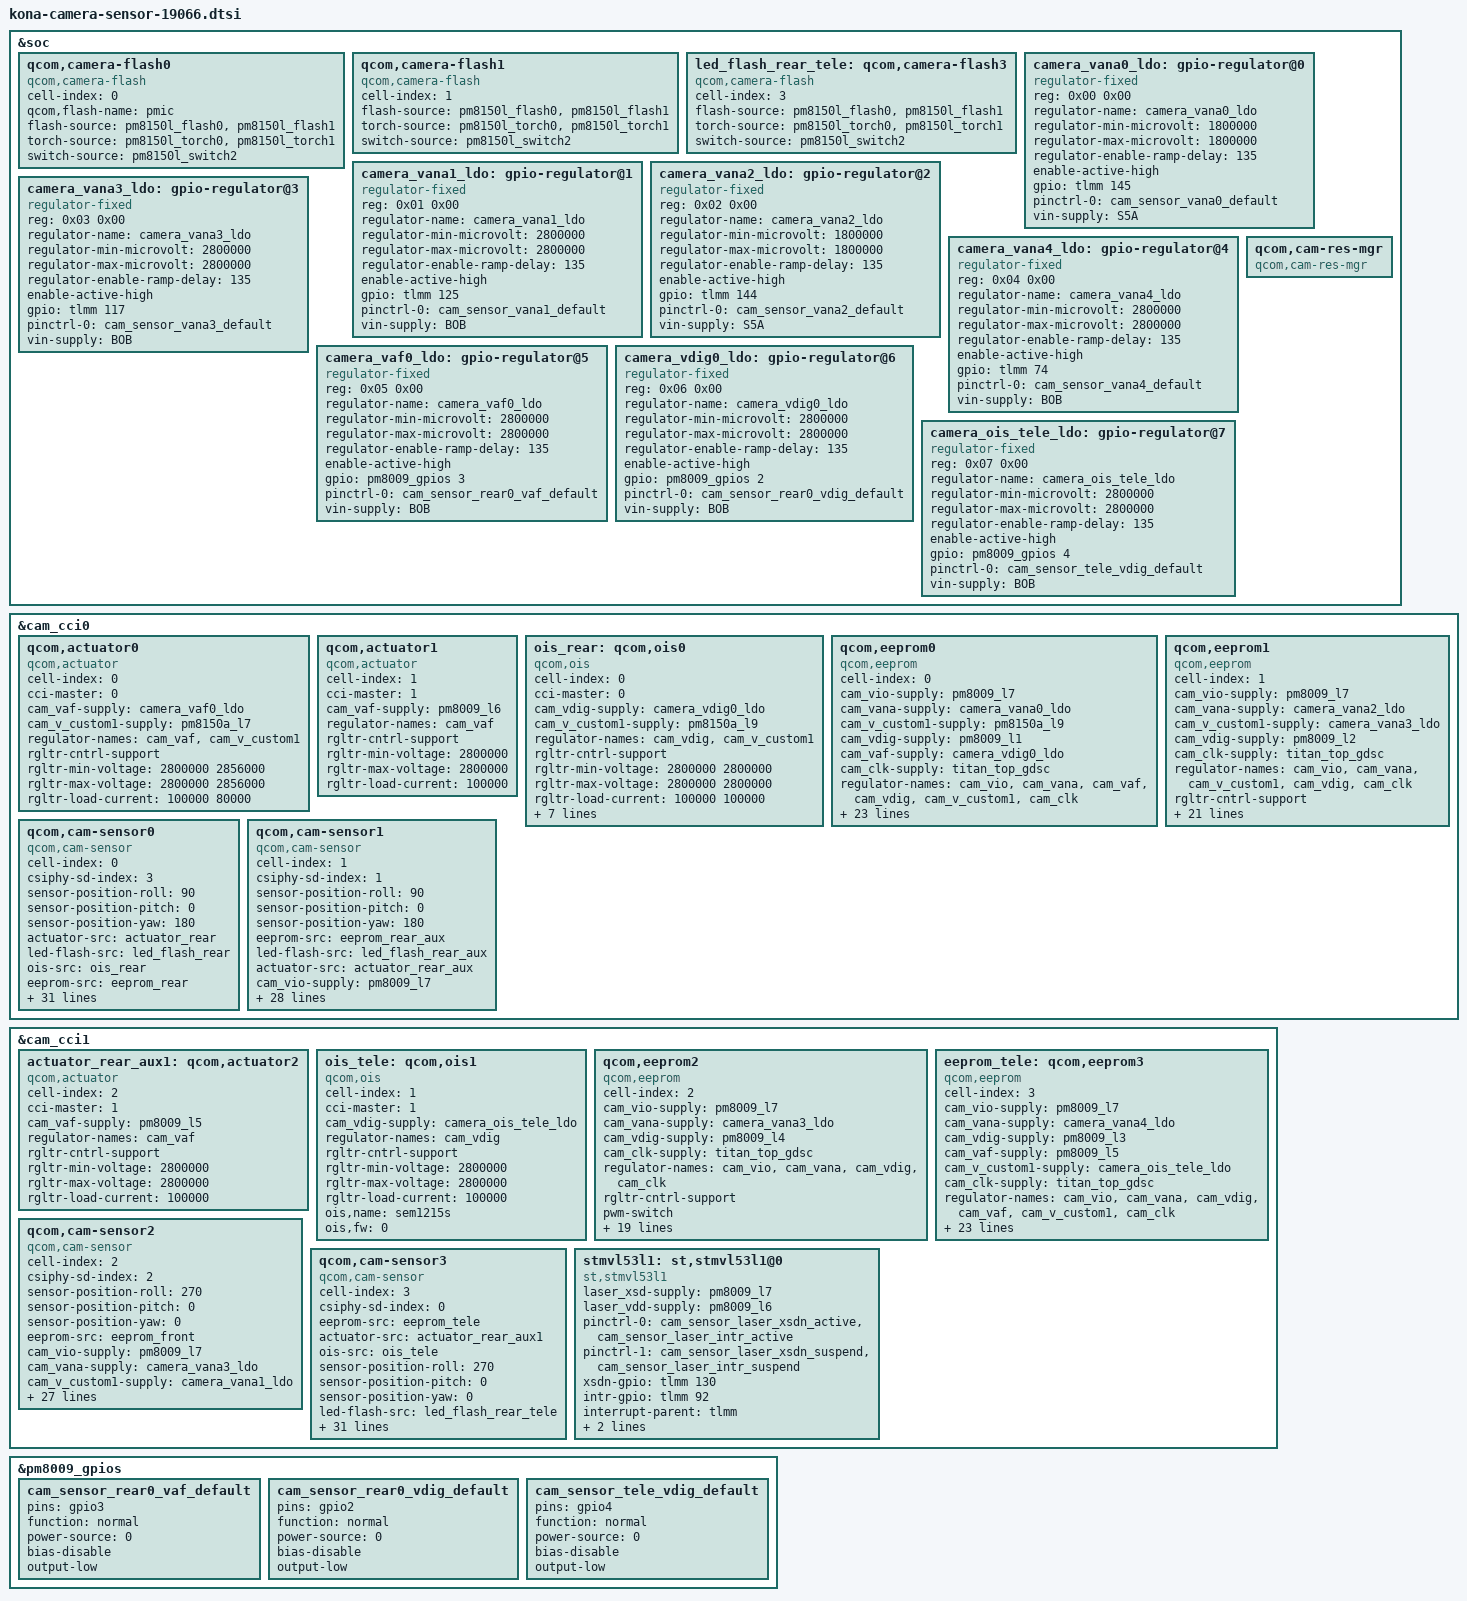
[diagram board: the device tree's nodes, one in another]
#include <dt-bindings/clock/qcom,camcc-kona.h>

&soc {
	qcom,camera-flash0 {
		cell-index = <0>;
		compatible = "qcom,camera-flash";
		qcom,flash-name = "pmic";
		flash-source = <&pm8150l_flash0 &pm8150l_flash1>;
		torch-source = <&pm8150l_torch0 &pm8150l_torch1>;
		switch-source = <&pm8150l_switch2>;
		status = "ok";
	};

	qcom,camera-flash1 {
		cell-index = <1>;
		compatible = "qcom,camera-flash";
		flash-source = <&pm8150l_flash0 &pm8150l_flash1>;
		torch-source = <&pm8150l_torch0 &pm8150l_torch1>;
		switch-source = <&pm8150l_switch2>;
		status = "ok";
	};

	led_flash_rear_tele: qcom,camera-flash3 {
		cell-index = <3>;
		compatible = "qcom,camera-flash";
		flash-source = <&pm8150l_flash0 &pm8150l_flash1>;
		torch-source = <&pm8150l_torch0 &pm8150l_torch1>;
		switch-source = <&pm8150l_switch2>;
		status = "ok";
	};

	camera_vana0_ldo: gpio-regulator@0 {
		compatible = "regulator-fixed";
		reg = <0x00 0x00>;
		regulator-name = "camera_vana0_ldo";
		regulator-min-microvolt = <1800000>;
		regulator-max-microvolt = <1800000>;
		regulator-enable-ramp-delay = <135>;
		enable-active-high;
		gpio = <&tlmm 145 0>;
		pinctrl-names = "default";
		pinctrl-0 = <&cam_sensor_vana0_default>;
		vin-supply = <&S5A>;
	};
	camera_vana1_ldo: gpio-regulator@1 {
		compatible = "regulator-fixed";
		reg = <0x01 0x00>;
		regulator-name = "camera_vana1_ldo";
		regulator-min-microvolt = <2800000>;
		regulator-max-microvolt = <2800000>;
		regulator-enable-ramp-delay = <135>;
		enable-active-high;
		gpio = <&tlmm 125 0>;
		pinctrl-names = "default";
		pinctrl-0 = <&cam_sensor_vana1_default>;
		vin-supply = <&BOB>;
	};
	camera_vana2_ldo: gpio-regulator@2 {
		compatible = "regulator-fixed";
		reg = <0x02 0x00>;
		regulator-name = "camera_vana2_ldo";
		regulator-min-microvolt = <1800000>;
		regulator-max-microvolt = <1800000>;
		regulator-enable-ramp-delay = <135>;
		enable-active-high;
		gpio = <&tlmm 144 0>;
		pinctrl-names = "default";
		pinctrl-0 = <&cam_sensor_vana2_default>;
		vin-supply = <&S5A>;
	};
	camera_vana3_ldo: gpio-regulator@3 {
		compatible = "regulator-fixed";
		reg = <0x03 0x00>;
		regulator-name = "camera_vana3_ldo";
		regulator-min-microvolt = <2800000>;
		regulator-max-microvolt = <2800000>;
		regulator-enable-ramp-delay = <135>;
		enable-active-high;
		gpio = <&tlmm 117 0>;
		pinctrl-names = "default";
		pinctrl-0 = <&cam_sensor_vana3_default>;
		vin-supply = <&BOB>;
	};
	camera_vana4_ldo: gpio-regulator@4 {
		compatible = "regulator-fixed";
		reg = <0x04 0x00>;
		regulator-name = "camera_vana4_ldo";
		regulator-min-microvolt = <2800000>;
		regulator-max-microvolt = <2800000>;
		regulator-enable-ramp-delay = <135>;
		enable-active-high;
		gpio = <&tlmm 74 0>;
		pinctrl-names = "default";
		pinctrl-0 = <&cam_sensor_vana4_default>;
		vin-supply = <&BOB>;
	};
	camera_vaf0_ldo: gpio-regulator@5 {
		compatible = "regulator-fixed";
		reg = <0x05 0x00>;
		regulator-name = "camera_vaf0_ldo";
		regulator-min-microvolt = <2800000>;
		regulator-max-microvolt = <2800000>;
		regulator-enable-ramp-delay = <135>;
		enable-active-high;
		gpio = <&pm8009_gpios 3 0>;
		pinctrl-names = "default";
		pinctrl-0 = <&cam_sensor_rear0_vaf_default>;
		vin-supply = <&BOB>;
	};

	camera_vdig0_ldo: gpio-regulator@6 {
		compatible = "regulator-fixed";
		reg = <0x06 0x00>;
		regulator-name = "camera_vdig0_ldo";
		regulator-min-microvolt = <2800000>;
		regulator-max-microvolt = <2800000>;
		regulator-enable-ramp-delay = <135>;
		enable-active-high;
		gpio = <&pm8009_gpios 2 0>;
		pinctrl-names = "default";
		pinctrl-0 = <&cam_sensor_rear0_vdig_default>;
		vin-supply = <&BOB>;
	};

	camera_ois_tele_ldo: gpio-regulator@7 {
		compatible = "regulator-fixed";
		reg = <0x07 0x00>;
		regulator-name = "camera_ois_tele_ldo";
		regulator-min-microvolt = <2800000>;
		regulator-max-microvolt = <2800000>;
		regulator-enable-ramp-delay = <135>;
		enable-active-high;
		gpio = <&pm8009_gpios 4 0>;
		pinctrl-names = "default";
		pinctrl-0 = <&cam_sensor_tele_vdig_default>;
		vin-supply = <&BOB>;
	};

	qcom,cam-res-mgr {
		compatible = "qcom,cam-res-mgr";
		status = "ok";
	};
};

&cam_cci0 {
	qcom,actuator0 {
		cell-index = <0>;
		compatible = "qcom,actuator";
		cci-master = <0>;
		cam_vaf-supply = <&camera_vaf0_ldo>;
		cam_v_custom1-supply = <&pm8150a_l7>;
		regulator-names = "cam_vaf", "cam_v_custom1";
		rgltr-cntrl-support;
		rgltr-min-voltage = <2800000 2856000>;
		rgltr-max-voltage = <2800000 2856000>;
		rgltr-load-current = <100000 80000>;
	};

	qcom,actuator1 {
		cell-index = <1>;
		compatible = "qcom,actuator";
		cci-master = <1>;
		cam_vaf-supply = <&pm8009_l6>;
		regulator-names = "cam_vaf";
		rgltr-cntrl-support;
		rgltr-min-voltage = <2800000>;
		rgltr-max-voltage = <2800000>;
		rgltr-load-current = <100000>;
	};

	ois_rear: qcom,ois0 {
		cell-index = <0>;
		compatible = "qcom,ois";
		cci-master = <0>;
		cam_vdig-supply = <&camera_vdig0_ldo>;
		cam_v_custom1-supply = <&pm8150a_l9>;
		regulator-names = "cam_vdig", "cam_v_custom1";
		rgltr-cntrl-support;
		rgltr-min-voltage = <2800000 2800000>;
		rgltr-max-voltage = <2800000 2800000>;
		rgltr-load-current = <100000 100000>;
		ois_gyro,position=<3>;
		ois_gyro,type=<3>;
		ois,type=<0>;
		ois,name="LC898128";
		ois_module,vendor=<1>;
		ois_actuator,vednor=<2>;
		ois,fw=<1>;
		status = "ok";
	};

	qcom,eeprom0 {
		cell-index = <0>;
		compatible = "qcom,eeprom";
		cam_vio-supply = <&pm8009_l7>;
		cam_vana-supply = <&camera_vana0_ldo>;
		cam_v_custom1-supply = <&pm8150a_l9>;
		cam_vdig-supply = <&pm8009_l1>;
		cam_vaf-supply = <&camera_vdig0_ldo>;
		cam_clk-supply = <&titan_top_gdsc>;
		regulator-names = "cam_vio", "cam_vana", "cam_vaf", "cam_vdig", "cam_v_custom1",
			"cam_clk";
		rgltr-cntrl-support;
		pwm-switch;
		rgltr-min-voltage = <1800000 1800000 2800000 1100000 2800000 0>;
		rgltr-max-voltage = <1800000 1800000 2800000 1100000 2800000 0>;
		rgltr-load-current = <0 80000 100000 105000 80000 0>;
		gpio-no-mux = <0>;
		pinctrl-names = "cam_default", "cam_suspend";
		pinctrl-0 = <&cam_sensor_mclk0_active
				&cam_sensor_active_rear>;
		pinctrl-1 = <&cam_sensor_mclk0_suspend
				&cam_sensor_suspend_rear>;
		gpios = <&tlmm 94 0>,
			<&tlmm 90 0>;
		gpio-reset = <1>;
		gpio-req-tbl-num = <0 1>;
		gpio-req-tbl-flags = <1 0>;
		gpio-req-tbl-label = "CAMIF_MCLK0",
					"CAM_RESET0";
		sensor-mode = <0>;
		cci-master = <0>;
		status = "ok";
		clocks = <&clock_camcc CAM_CC_MCLK0_CLK>;
		clock-names = "cam_clk";
		clock-cntl-level = "turbo";
		clock-rates = <19200000>;
	};

	qcom,eeprom1 {
		cell-index = <1>;
		compatible = "qcom,eeprom";
		cam_vio-supply = <&pm8009_l7>;
		cam_vana-supply = <&camera_vana2_ldo>;
		cam_v_custom1-supply = <&camera_vana3_ldo>;
		cam_vdig-supply = <&pm8009_l2>;
		cam_clk-supply = <&titan_top_gdsc>;
		regulator-names = "cam_vio", "cam_vana", "cam_v_custom1", "cam_vdig",
			"cam_clk";
		rgltr-cntrl-support;
		pwm-switch;
		rgltr-min-voltage = <1800000 1800000 2800000 1100000 0>;
		rgltr-max-voltage = <1800000 1800000 2800000 1100000 0>;
		rgltr-load-current = <0 80000 0 105000 0>;
		gpio-no-mux = <0>;
		pinctrl-names = "cam_default", "cam_suspend";
		pinctrl-0 = <&cam_sensor_mclk1_active
				&cam_sensor_active_rst2>;
		pinctrl-1 = <&cam_sensor_mclk1_suspend
				&cam_sensor_suspend_rst2>;
		gpios = <&tlmm 95 0>,
			<&tlmm 78 0>;
		gpio-reset = <1>;
		gpio-req-tbl-num = <0 1>;
		gpio-req-tbl-flags = <1 0>;
		gpio-req-tbl-label = "CAMIF_MCLK1",
					"CAM_RESET1";
		sensor-mode = <0>;
		cci-master = <1>;
		status = "ok";
		clocks = <&clock_camcc CAM_CC_MCLK1_CLK>;
		clock-names = "cam_clk";
		clock-cntl-level = "turbo";
		clock-rates = <19200000>;
	};

	qcom,cam-sensor0 {
		cell-index = <0>;
		compatible = "qcom,cam-sensor";
		csiphy-sd-index = <3>;
		sensor-position-roll = <90>;
		sensor-position-pitch = <0>;
		sensor-position-yaw = <180>;
		actuator-src = <&actuator_rear>;
		led-flash-src = <&led_flash_rear>;
		ois-src = <&ois_rear>;
		eeprom-src = <&eeprom_rear>;
		cam_vio-supply = <&pm8009_l7>;
		cam_vana-supply = <&camera_vana0_ldo>;
		cam_v_custom1-supply = <&camera_vana1_ldo>;
		cam_v_custom2-supply = <&pm8150a_l9>;
		cam_vdig-supply = <&pm8009_l1>;
		cam_clk-supply = <&titan_top_gdsc>;
		regulator-names = "cam_vio", "cam_vana", "cam_v_custom1", "cam_v_custom2", "cam_vdig",
			"cam_clk";
		rgltr-cntrl-support;
		pwm-switch;
		rgltr-min-voltage = <1800000 1800000 2800000 2800000 1100000 0>;
		rgltr-max-voltage = <1800000 1800000 2800000 2800000 1100000 0>;
		rgltr-load-current = <0 80000 0 80000 105000 0>;
		gpio-no-mux = <0>;
		pinctrl-names = "cam_default", "cam_suspend";
		pinctrl-0 = <&cam_sensor_mclk0_active
				&cam_sensor_active_rear>;
		pinctrl-1 = <&cam_sensor_mclk0_suspend
				&cam_sensor_suspend_rear>;
		gpios = <&tlmm 94 0>,
			<&tlmm 90 0>;
		gpio-reset = <1>;
		gpio-req-tbl-num = <0 1>;
		gpio-req-tbl-flags = <1 0>;
		gpio-req-tbl-label = "CAMIF_MCLK0",
					"CAM_RESET0";
		sensor-mode = <0>;
		cci-master = <0>;
		status = "ok";
		clocks = <&clock_camcc CAM_CC_MCLK0_CLK>;
		clock-names = "cam_clk";
		clock-cntl-level = "turbo";
		clock-rates = <19200000>;
	};

	qcom,cam-sensor1 {
		cell-index = <1>;
		compatible = "qcom,cam-sensor";
		csiphy-sd-index = <1>;
		sensor-position-roll = <90>;
		sensor-position-pitch = <0>;
		sensor-position-yaw = <180>;
		eeprom-src = <&eeprom_rear_aux>;
		led-flash-src = <&led_flash_rear_aux>;
		actuator-src = <&actuator_rear_aux>;
		cam_vio-supply = <&pm8009_l7>;
		cam_vana-supply = <&camera_vana2_ldo>;
		cam_v_custom1-supply = <&camera_vana3_ldo>;
		cam_vdig-supply = <&pm8009_l2>;
		cam_clk-supply = <&titan_top_gdsc>;
		regulator-names = "cam_vio", "cam_vana", "cam_v_custom1", "cam_vdig",
			"cam_clk";
		rgltr-cntrl-support;
		pwm-switch;
		rgltr-min-voltage = <1800000 1800000 2800000 1100000 0>;
		rgltr-max-voltage = <1800000 1800000 2800000 1100000 0>;
		rgltr-load-current = <0 80000 0 105000 0>;
		gpio-no-mux = <0>;
		pinctrl-names = "cam_default", "cam_suspend";
		pinctrl-0 = <&cam_sensor_mclk1_active
				&cam_sensor_active_rst2>;
		pinctrl-1 = <&cam_sensor_mclk1_suspend
				&cam_sensor_suspend_rst2>;
		gpios = <&tlmm 95 0>,
			<&tlmm 78 0>;
		gpio-reset = <1>;
		gpio-req-tbl-num = <0 1>;
		gpio-req-tbl-flags = <1 0>;
		gpio-req-tbl-label = "CAMIF_MCLK1",
					"CAM_RESET1";
		sensor-mode = <0>;
		cci-master = <1>;
		status = "ok";
		clocks = <&clock_camcc CAM_CC_MCLK1_CLK>;
		clock-names = "cam_clk";
		clock-cntl-level = "turbo";
		clock-rates = <19200000>;
	};
};

&cam_cci1 {
	actuator_rear_aux1: qcom,actuator2 {
		cell-index = <2>;
		compatible = "qcom,actuator";
		cci-master = <1>;
		cam_vaf-supply = <&pm8009_l5>;
		regulator-names = "cam_vaf";
		rgltr-cntrl-support;
		rgltr-min-voltage = <2800000>;
		rgltr-max-voltage = <2800000>;
		rgltr-load-current = <100000>;
	};

	ois_tele: qcom,ois1 {
		cell-index = <1>;
		compatible = "qcom,ois";
		cci-master = <1>;
		cam_vdig-supply = <&camera_ois_tele_ldo>;
		regulator-names = "cam_vdig";
		rgltr-cntrl-support;
		rgltr-min-voltage = <2800000>;
		rgltr-max-voltage = <2800000>;
		rgltr-load-current = <100000>;
		ois,name="sem1215s";
		ois,fw=<0>;
		status = "ok";
	};

	qcom,eeprom2 {
		cell-index = <2>;
		compatible = "qcom,eeprom";
		cam_vio-supply = <&pm8009_l7>;
		cam_vana-supply = <&camera_vana3_ldo>;
		cam_vdig-supply = <&pm8009_l4>;
		cam_clk-supply = <&titan_top_gdsc>;
		regulator-names = "cam_vio", "cam_vana", "cam_vdig",
			"cam_clk";
		rgltr-cntrl-support;
		pwm-switch;
		rgltr-min-voltage = <1800000 2800000 1050000 0>;
		rgltr-max-voltage = <1800000 2800000 1050000 0>;
		rgltr-load-current = <0 80000 105000 0>;
		gpio-no-mux = <0>;
		pinctrl-names = "cam_default", "cam_suspend";
		pinctrl-0 = <&cam_sensor_mclk2_active
				 &cam_sensor_active_rear_aux>;
		pinctrl-1 = <&cam_sensor_mclk2_suspend
				 &cam_sensor_suspend_rear_aux>;
		gpios = <&tlmm 96 0>,
			<&tlmm 76 0>;
		gpio-reset = <1>;
		gpio-req-tbl-num = <0 1>;
		gpio-req-tbl-flags = <1 0>;
		gpio-req-tbl-label = "CAMIF_MCLK2",
					"CAM_RESET2";
		sensor-mode = <0>;
		cci-device = <1>;
		cci-master = <0>;
		status = "ok";
		clocks = <&clock_camcc CAM_CC_MCLK2_CLK>;
		clock-names = "cam_clk";
		clock-cntl-level = "turbo";
		clock-rates = <19200000>;
	};

	eeprom_tele: qcom,eeprom3 {
		cell-index = <3>;
		compatible = "qcom,eeprom";
		cam_vio-supply = <&pm8009_l7>;
		cam_vana-supply = <&camera_vana4_ldo>;
		cam_vdig-supply = <&pm8009_l3>;
		cam_vaf-supply = <&pm8009_l5>;
		cam_v_custom1-supply = <&camera_ois_tele_ldo>;
		cam_clk-supply = <&titan_top_gdsc>;
		regulator-names = "cam_vio", "cam_vana", "cam_vdig", "cam_vaf", "cam_v_custom1",
			"cam_clk";
		rgltr-cntrl-support;
		rgltr-min-voltage = <1800000 2800000 1050000 2800000 2800000 0>;
		rgltr-max-voltage = <1800000 2800000 1050000 2800000 2800000 0>;
		rgltr-load-current = <0 80000 105000 80000 80000 0>;
		gpio-no-mux = <0>;
		pinctrl-names = "cam_default", "cam_suspend";
		pinctrl-0 = <&cam_sensor_mclk3_active
				 &cam_sensor_active_3>;
		pinctrl-1 = <&cam_sensor_mclk3_suspend
				 &cam_sensor_suspend_3>;
		gpios = <&tlmm 97 0>,
			<&tlmm 98 0>;
		gpio-reset = <1>;
		gpio-req-tbl-num = <0 1>;
		gpio-req-tbl-flags = <1 0>;
		gpio-req-tbl-label = "CAMIF_MCLK3",
					"CAM_RESET3";
		sensor-mode = <0>;
		cci-device = <0>;
		cci-master = <1>;
		status = "ok";
		clocks = <&clock_camcc CAM_CC_MCLK3_CLK>;
		clock-names = "cam_clk";
		clock-cntl-level = "turbo";
		clock-rates = <19200000>;
	};

	qcom,cam-sensor2 {
		cell-index = <2>;
		compatible = "qcom,cam-sensor";
		csiphy-sd-index = <2>;
		sensor-position-roll = <270>;
		sensor-position-pitch = <0>;
		sensor-position-yaw = <0>;
		eeprom-src = <&eeprom_front>;
		cam_vio-supply = <&pm8009_l7>;
		cam_vana-supply = <&camera_vana3_ldo>;
		cam_v_custom1-supply = <&camera_vana1_ldo>;
		cam_vdig-supply = <&pm8009_l4>;
		cam_clk-supply = <&titan_top_gdsc>;
		regulator-names = "cam_vio", "cam_vana", "cam_v_custom1", "cam_vdig",
			"cam_clk";
		rgltr-cntrl-support;
		pwm-switch;
		rgltr-min-voltage = <1800000 2800000 2800000 1050000 0>;
		rgltr-max-voltage = <1800000 2800000 2800000 1050000 0>;
		rgltr-load-current = <0 80000 80000 105000 0>;
		gpio-no-mux = <0>;
		pinctrl-names = "cam_default", "cam_suspend";
		pinctrl-0 = <&cam_sensor_mclk2_active
				 &cam_sensor_active_rear_aux>;
		pinctrl-1 = <&cam_sensor_mclk2_suspend
				 &cam_sensor_suspend_rear_aux>;
		gpios = <&tlmm 96 0>,
			<&tlmm 76 0>;
		gpio-reset = <1>;
		gpio-req-tbl-num = <0 1>;
		gpio-req-tbl-flags = <1 0>;
		gpio-req-tbl-label = "CAMIF_MCLK2",
					"CAM_RESET2";
		sensor-mode = <0>;
		cci-device = <1>;
		cci-master = <0>;
		status = "ok";
		clocks = <&clock_camcc CAM_CC_MCLK2_CLK>;
		clock-names = "cam_clk";
		clock-cntl-level = "turbo";
		clock-rates = <19200000>;
	};

	qcom,cam-sensor3 {
		cell-index = <3>;
		compatible = "qcom,cam-sensor";
		csiphy-sd-index = <0>;
		eeprom-src = <&eeprom_tele>;
		actuator-src = <&actuator_rear_aux1>;
		ois-src = <&ois_tele>;
		sensor-position-roll = <270>;
		sensor-position-pitch = <0>;
		sensor-position-yaw = <0>;
		led-flash-src = <&led_flash_rear_tele>;
		cam_vio-supply = <&pm8009_l7>;
		cam_vana-supply = <&camera_vana4_ldo>;
		cam_vdig-supply = <&pm8009_l3>;
		cam_vaf-supply = <&pm8009_l5>;
		cam_v_custom1-supply = <&camera_ois_tele_ldo>;
		cam_clk-supply = <&titan_top_gdsc>;
		regulator-names = "cam_vio", "cam_vana", "cam_vdig", "cam_vaf", "cam_v_custom1",
			"cam_clk";
		rgltr-cntrl-support;
		rgltr-min-voltage = <1800000 2800000 1050000 2800000 2800000 0>;
		rgltr-max-voltage = <1800000 2800000 1050000 2800000 2800000 0>;
		rgltr-load-current = <0 80000 105000 80000 80000 0>;
		gpio-no-mux = <0>;
		pinctrl-names = "cam_default", "cam_suspend";
		pinctrl-0 = <&cam_sensor_mclk3_active
				 &cam_sensor_active_3>;
		pinctrl-1 = <&cam_sensor_mclk3_suspend
				 &cam_sensor_suspend_3>;
		gpios = <&tlmm 97 0>,
			<&tlmm 98 0>;
		gpio-reset = <1>;
		gpio-req-tbl-num = <0 1>;
		gpio-req-tbl-flags = <1 0>;
		gpio-req-tbl-label = "CAMIF_MCLK3",
					"CAM_RESET3";
		sensor-mode = <0>;
		cci-device = <0>;
		cci-master = <1>;
		status = "ok";
		clocks = <&clock_camcc CAM_CC_MCLK3_CLK>;
		clock-names = "cam_clk";
		clock-cntl-level = "turbo";
		clock-rates = <19200000>;
	};
    stmvl53l1: st,stmvl53l1@0 {
        compatible = "st,stmvl53l1";
        laser_xsd-supply = <&pm8009_l7>;
        laser_vdd-supply = <&pm8009_l6>;

        pinctrl-names = "laser_default", "laser_suspend";
        pinctrl-0 = <&cam_sensor_laser_xsdn_active
                     &cam_sensor_laser_intr_active>;
        pinctrl-1 = <&cam_sensor_laser_xsdn_suspend
                     &cam_sensor_laser_intr_suspend>;

        xsdn-gpio = <&tlmm 130 GPIO_ACTIVE_HIGH>;
        intr-gpio = <&tlmm 92 GPIO_ACTIVE_HIGH>;
        interrupt-parent = <&tlmm>;
        cci-device = <1>;
        cci-master = <0>;
        status = "ok";
    };
};
&pm8009_gpios {
	cam_sensor_rear0_vaf_default: cam_sensor_rear0_vaf_default {
		pins = "gpio3";
		function = "normal";
		power-source = <0>;
		bias-disable; //No Pull
		output-low;
	};

	cam_sensor_rear0_vdig_default: cam_sensor_rear0_vdig_default {
		pins = "gpio2";
		function = "normal";
		power-source = <0>;
		bias-disable; //No Pull
		output-low;
	};

	cam_sensor_tele_vdig_default:cam_sensor_tele_vdig_default {
		pins = "gpio4";
		function = "normal";
		power-source = <0>;
		bias-disable; //No Pull
		output-low;
	};
};
